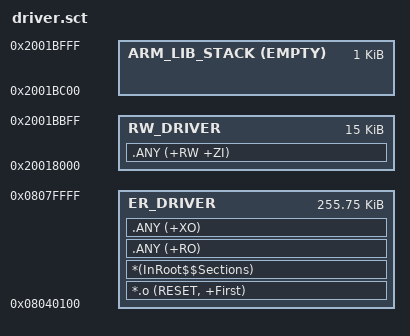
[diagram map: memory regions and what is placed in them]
; *************************************************************
; ***  本文件由 tools/gen_scatter.py 自动生成，请勿手工编辑  ***
; ***  配置源头: config/svcrt_partition.h                    ***
; ***  修改布局请改配置头，然后重新编译（编译前会自动重新生成） ***
; *************************************************************

LR_DRIVER 0x08040100 0x0003FF00  {
  ER_DRIVER 0x08040100 0x0003FF00  {
   *.o (RESET, +First)          ; 启动入口向量表必须位于分区首地址
   *(InRoot$$Sections)
   .ANY (+RO)
   .ANY (+XO)
  }
  RW_DRIVER 0x20018000 0x00003C00  {   ; 上限已扣除栈区，编译期不会侵占栈
   .ANY (+RW +ZI)
  }
  ARM_LIB_STACK 0x2001C000 EMPTY -0x400 {   ; 栈 1024 字节（与内核推导的栈顶一致）
  }
}
